# ATSAMRH71F20C register map
Vendor: Microchip Technology; Series: SAMRH71; File version: 0
CPU: CM7 r1p1, little endian, MPU, FPU, 3 interrupt priority bits
Registers are 32-bit, read-write, reset 0x0 unless marked. A register's access mark holds for its fields unless they carry their own. Offsets are from the block's base; [hi:lo] are bit positions; {n}, {i} and the like mark numbered series.

## NMIC — Non-maskable Interrupt Controller
Base 0x400A8000; register names take the prefix NMIC_
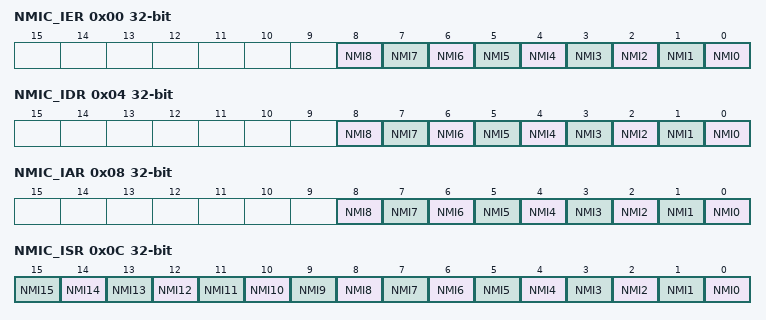
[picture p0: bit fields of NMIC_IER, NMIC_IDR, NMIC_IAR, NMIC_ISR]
0x00 NMIC_IER wo — Interrupt Enable Register
  [n] NMI{n} (n=0..8) — Non-maskable Interrupt {n} Enable
0x04 NMIC_IDR wo — Interrupt Disable Register
  [n] NMI{n} (n=0..8) — Non-maskable Interrupt {n} Disable
0x08 NMIC_IAR ro — Interrupt Active Register
  [n] NMI{n} (n=0..8) — Active Interrupt {n}
0x0C NMIC_ISR ro — Interrupt Status Register
  [n] NMI{n} (n=0..15) — Non-maskable Interrupt Source {n} Pending (cleared on read)
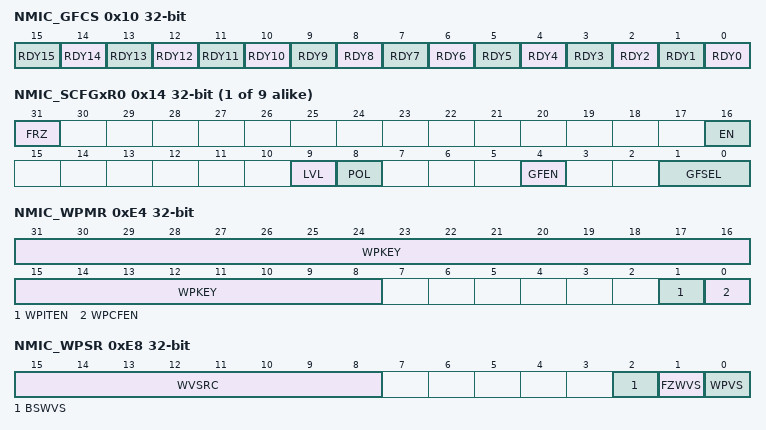
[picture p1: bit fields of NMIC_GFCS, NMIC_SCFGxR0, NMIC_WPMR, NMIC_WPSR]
0x10 NMIC_GFCS ro — Glitch Filter Configuration Status Register
  [n] RDY{n} (n=0..15) — Filter {n} Configuration Ready
{0x14+4i} NMIC_SCFGxR{i} (i=0..8) — Source Configuration Register 0 {i}
  [31] FRZ — Interrupt Line Freeze
  [16] EN — Source Enable
  [9] LVL — Level Detection (LVL bit is read-only in NMIC_SCFG0 to 8)
  [8] POL — Polarity (POL bit is read-only in NMIC_SCFG0 to 8)
  [4] GFEN — Glitch Filter Enable (GFEN bit is read-only in NMIC_SCFG0 to 8)
  [1:0] GFSEL — Glitch Filter Selector (GFSEL field is read-only in NMIC_SCFG0 to 8)
0xE4 NMIC_WPMR — Write Protection Mode Register
  [31:8] WPKEY — Write Protection Key
    0x4E4D49=PASSWD (Writing any other value in this field aborts the write operation of the WPCFEN and WPITEN bit. Always reads as 0.)
  [1] WPITEN — Write Protection Interrupt Enable
  [0] WPCFEN — Write Protection Configuration Enable
0xE8 NMIC_WPSR ro — Write Protection Status Register
  [15:8] WVSRC — Write Violation Source
  [2] BSWVS — Busy Register Write Violation Status
  [1] FZWVS — Frozen Register Write Violation Status
  [0] WPVS — Write Protection Register Violation Status

## RSTC — Reset Controller
Base 0x40100200; register names take the prefix RSTC_
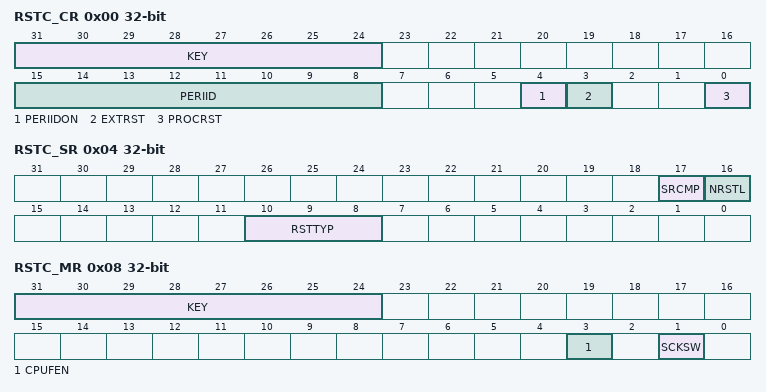
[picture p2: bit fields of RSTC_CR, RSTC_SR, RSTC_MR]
0x00 RSTC_CR wo — Control Register
  [31:24] KEY — System Reset Key
    165=PASSWD (Writing any other value in this field aborts the write operation.)
  [15:8] PERIID — Peripheral Identifier
  [4] PERIIDON — External Reset
  [3] EXTRST — External Reset
  [0] PROCRST — Processor Reset
0x04 RSTC_SR ro — Status Register
  [17] SRCMP — Software Reset Command in Progress
  [16] NRSTL — NRST Pin Level
  [10:8] RSTTYP — Reset Type
    0=GENERAL_RST (First powerup reset); 2=WDT_RST (Watchdog fault occurred); 3=SOFT_RST (Processor reset required by the software); 4=USER_RST (NRST pin detected low); 6=CPU_FAIL_RST (CPU clock failure detection occurred); 7=SLCK_XTAL_RST (32.768 kHz crystal failure detection fault occurred)
0x08 RSTC_MR — Mode Register
  [31:24] KEY — Write Access Password
    165=PASSWD (Writing any other value in this field aborts the write operation.Always reads as 0.)
  [3] CPUFEN — CPU Fail Enable
  [1] SCKSW — Slow Clock Switching

## RTT — Real-time Timer
Base 0x40100230; register names take the prefix RTT_
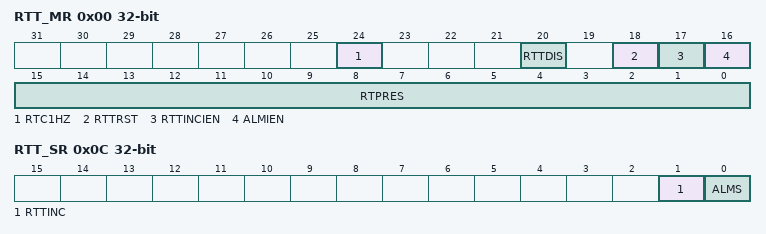
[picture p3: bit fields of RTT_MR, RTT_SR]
0x00 RTT_MR — Mode Register
  [24] RTC1HZ — Real-Time Clock 1Hz Clock Selection
  [20] RTTDIS — Real-time Timer Disable
  [18] RTTRST — Real-time Timer Restart
  [17] RTTINCIEN — Real-time Timer Increment Interrupt Enable
  [16] ALMIEN — Alarm Interrupt Enable
  [15:0] RTPRES — Real-time Timer Prescaler Value
0x04 RTT_AR — Alarm Register
  [31:0] ALMV — Alarm Value
0x08 RTT_VR ro — Value Register
  [31:0] CRTV — Current Real-time Value
0x0C RTT_SR ro — Status Register
  [1] RTTINC — Prescaler Roll-over Status (cleared on read)
  [0] ALMS — Real-time Alarm Status (cleared on read)

## SFR — Special Function Registers
Base 0x400A0000; register names take the prefix SFR_
0xA0 SFR_CAN0 — CAN0 MSB Base Address 0
  [31:16] EXT_MEM_ADDR — MSB Base Address
0xA4 SFR_CAN1 — CAN0 MSB Base Address 1
  [31:16] EXT_MEM_ADDR — MSB Base Address
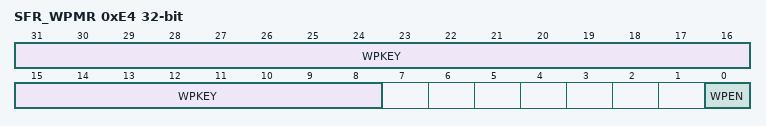
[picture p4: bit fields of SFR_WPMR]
0xE4 SFR_WPMR — Write Protection Mode Register
  [31:8] WPKEY — Write Protection Key
    0x534652=PASSWD (Writing any other value in this field aborts the write operation.Always reads as 0.)
  [0] WPEN — Write Protection Enable
